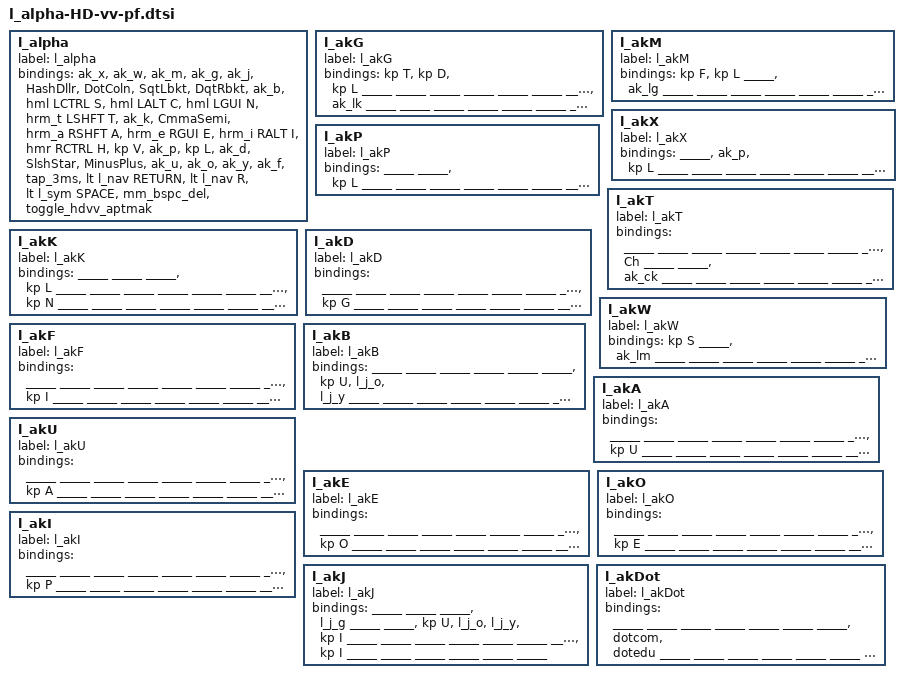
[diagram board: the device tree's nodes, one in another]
#define _____  &trans

                   l_alpha {
                            label = "l_alpha";
                            bindings = <
&ak_x         &ak_w        &ak_m        &ak_g           &ak_j            &HashDllr   &DotColn        &SqtLbkt       &DqtRbkt       &ak_b
&hml LCTRL S  &hml LALT C  &hml LGUI N  &hrm_t LSHFT T  &ak_k            &CmmaSemi   &hrm_a RSHFT A  &hrm_e RGUI E  &hrm_i RALT I  &hmr RCTRL H
&kp V         &ak_p        &kp L        &ak_d           &SlshStar        &MinusPlus  &ak_u           &ak_o          &ak_y          &ak_f
                           &tap_3ms        &lt l_nav RETURN    &lt l_nav R      &lt l_sym SPACE &mm_bspc_del &toggle_hdvv_aptmak
                            >;
                   };

                   l_akG {
                            label = "l_akG";
                            bindings = <
&kp T   &kp D   &kp L   _____   _____       _____   _____   _____   _____   _____
_____   _____   _____   _____   &ak_lk      _____   _____   _____   _____   _____
_____   _____   _____   _____   _____       _____   _____   _____   _____   _____
                _____   _____   _____       _____   _____   _____
                            >;
                   };
                   l_akM {
                            label = "l_akM";
                            bindings = <
&kp F   &kp L   _____   &ak_lg  _____       _____   _____   _____   _____   _____
_____   _____   _____   _____   _____       _____   _____   _____   _____   _____
_____   _____   _____   _____   _____       _____   _____   _____   _____   _____
                _____   _____   _____       _____   _____   _____
                            >;
                   };
                   l_akX {
                            label = "l_akX";
                            bindings = <
_____   &ak_p   &kp L   _____   _____       _____   _____   _____   _____   _____
_____   _____   _____   _____   _____       _____   _____   _____   _____   _____
_____   _____   _____   _____   _____       _____   _____   _____   _____   _____
                _____   _____   _____       _____   _____   _____
                            >;
                   };
                   l_akP {
                            label = "l_akP";
                            bindings = <
_____   _____   &kp L   _____   _____       _____   _____   _____   _____   _____
_____   _____   _____   _____   _____       _____   _____   _____   _____   _____
_____   _____   _____   _____   _____       _____   _____   _____   _____   _____
                _____   _____   _____       _____   _____   _____
                            >;
                   };
                   l_akT {
                            label = "l_akT";
                            bindings = <
_____   _____   _____   _____   _____       _____   _____   _____   _____   _____
_____   &Ch     _____   _____   &ak_ck      _____   _____   _____   _____   _____
_____   _____   _____   _____   _____       _____   _____   _____   _____   _____
                _____   _____   _____       _____   _____   _____
                            >;
                   };
                   l_akK {
                            label = "l_akK";
                            bindings = <
_____   _____   _____   &kp L   _____       _____   _____   _____   _____   _____
_____   _____   _____   &kp N   _____       _____   _____   _____   _____   _____
_____   _____   _____   _____   _____       _____   _____   _____   _____   _____
                _____   _____   _____       _____   _____   _____
                            >;
                   };
                   l_akD {
                            label = "l_akD";
                            bindings = <
_____   _____   _____   _____   _____       _____   _____   _____   _____   _____
_____   _____   _____   _____   _____       _____   _____   _____   _____   _____
_____   &kp G   _____   _____   _____       _____   _____   _____   _____   _____
                _____   _____   _____       _____   _____   _____
                            >;
                   };
                   l_akW {
                            label = "l_akW";
                            bindings = <
&kp S   _____   &ak_lm  _____   _____       _____   _____   _____   _____   _____
_____   _____   _____   _____   _____       _____   _____   _____   _____   _____
_____   _____   _____   _____   _____       _____   _____   _____   _____   _____
                _____   _____   _____       _____   _____   _____
                            >;
                   };
                   l_akF {
                            label = "l_akF";
                            bindings = <
_____   _____   _____   _____   _____       _____   _____   _____   _____   _____
_____   _____   _____   _____   _____       _____   _____   _____   _____   _____
_____   _____   _____   _____   _____       _____   _____   _____   &kp I   _____
                _____   _____   _____       _____   _____   _____
                            >;
                   };
                   l_akB {
                            label = "l_akB";
                            bindings = <
_____   _____   _____   _____   _____       _____   &kp U   &l_j_o  &l_j_y  _____
_____   _____   _____   _____   _____       _____   _____   _____   _____   _____
_____   _____   _____   _____   _____       _____   _____   _____   _____   _____
                _____   _____   _____       _____   _____   _____
                            >;
                   };
                   l_akA {
                            label = "l_akA";
                            bindings = <
_____   _____   _____   _____   _____       _____   _____   _____   _____   _____
_____   _____   _____   _____   _____       _____   _____   _____   _____   &kp U
_____   _____   _____   _____   _____       _____   _____   _____   _____   _____
                _____   _____   _____       _____   _____   _____
                            >;
                   };

                   l_akU {
                            label = "l_akU";
                            bindings = <
_____   _____   _____   _____   _____       _____   _____   _____   _____   _____
_____   _____   _____   _____   _____       _____   _____   _____   _____   &kp A
_____   _____   _____   _____   _____       _____   _____   _____   _____   _____
                _____   _____   _____       _____   _____   _____
                            >;
                   };

                   l_akE {
                            label = "l_akE";
                            bindings = <
_____   _____   _____   _____   _____       _____   _____   _____   _____   _____
_____   _____   _____   _____   _____       _____   _____   _____   _____   &kp O
_____   _____   _____   _____   _____       _____   _____   _____   _____   _____
                _____   _____   _____       _____   _____   _____
                            >;
                   };
                   l_akO {
                            label = "l_akO";
                            bindings = <
_____   _____   _____   _____   _____       _____   _____   _____   _____   _____
_____   _____   _____   _____   _____       _____   _____   _____   _____   &kp E
_____   _____   _____   _____   _____       _____   _____   _____   _____   _____
                _____   _____   _____       _____   _____   _____
                            >;
                   };
                   l_akI {
                            label = "l_akI";
                            bindings = <
_____   _____   _____   _____   _____       _____   _____   _____   _____   _____
_____   _____   _____   _____   _____       _____   _____   _____   _____   &kp P
_____   _____   _____   _____   _____       _____   _____   _____   _____   _____
                _____   _____   _____       _____   _____   _____
                            >;
                   };
                   l_akJ {
                            label = "l_akJ";
                            bindings = <
_____   _____   _____   &l_j_g  _____       _____   &kp U   &l_j_o  &l_j_y  &kp I
_____   _____   _____   _____   _____       _____   _____   _____   _____   _____
_____   _____   _____   _____   _____       _____   _____   _____   _____   &kp I
                _____   _____   _____       _____   _____   _____
                            >;
                   };

                   l_akDot {
                            label = "l_akDot";
                            bindings = <
_____   _____   _____   _____   _____       _____   _____   &dotcom &dotedu _____
_____   _____   _____   _____   _____       _____   _____   _____   _____   _____
_____   _____   _____   _____   _____       _____   _____   _____   _____   _____
                _____   _____   _____       _____   _____   _____
                            >;
                   };
